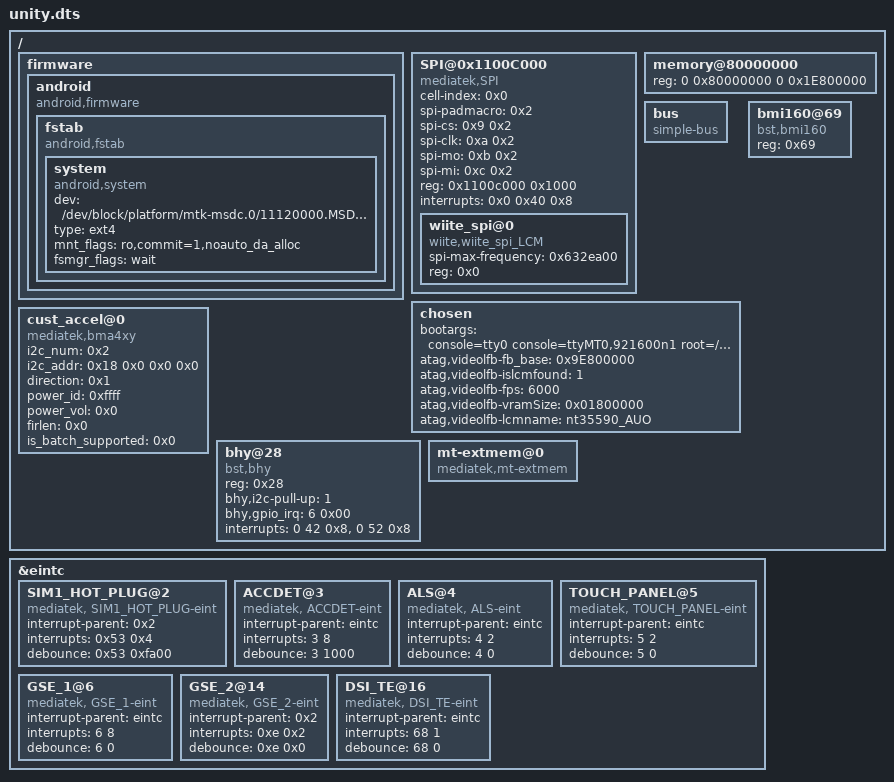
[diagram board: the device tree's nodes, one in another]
/dts-v1/;

/include/ "mt6580.dtsi"

&eintc {
	SIM1_HOT_PLUG@2 {
		compatible = "mediatek, SIM1_HOT_PLUG-eint";
		interrupt-parent = <0x2>;
		interrupts = <0x53 0x4>;
		debounce = <0x53 0xfa00>;
	};

	ACCDET@3 {
		compatible = "mediatek, ACCDET-eint";
		interrupt-parent = <&eintc>;
		interrupts = <3 8>;
		debounce = <3 1000>;
	};

	ALS@4 {
		compatible = "mediatek, ALS-eint";
		interrupt-parent = <&eintc>;
		interrupts = <4 2>;
		debounce = <4 0>;
	};

	TOUCH_PANEL@5 {
		compatible = "mediatek, TOUCH_PANEL-eint";
		interrupt-parent = <&eintc>;
		interrupts = <5 2>;
		debounce = <5 0>;
	};

	GSE_1@6 {
		compatible = "mediatek, GSE_1-eint";
		interrupt-parent = <&eintc>;
		interrupts = <6 8>;
		debounce = <6 0>;
	};

	GSE_2@14 {
		compatible = "mediatek, GSE_2-eint";
		interrupt-parent = <0x2>;
		interrupts = <0xe 0x2>;
		debounce = <0xe 0x0>;
	};

	DSI_TE@16 {
		compatible = "mediatek, DSI_TE-eint";
		interrupt-parent = <&eintc>;
		interrupts = <68 1>;
		debounce = <68 0>;
	};

};

/ {

	firmware {
		android {
			compatible = "android,firmware";
			fstab {
				compatible = "android,fstab";
				system {
					compatible = "android,system";
					dev = "/dev/block/platform/mtk-msdc.0/11120000.MSDC0/by-name/system";
					type = "ext4";
					mnt_flags = "ro,commit=1,noauto_da_alloc";
					fsmgr_flags = "wait";
				};
			};
		};
	};

	SPI@0x1100C000 {
		compatible = "mediatek,SPI";
		cell-index = <0x0>;
		spi-padmacro = <0x2>;
		spi-cs = <0x9 0x2>;
		spi-clk = <0xa 0x2>;
		spi-mo = <0xb 0x2>;
		spi-mi = <0xc 0x2>;
		reg = <0x1100c000 0x1000>;
		interrupts = <0x0 0x40 0x8>;

		wiite_spi@0 {
			compatible = "wiite,wiite_spi_LCM";
			spi-max-frequency = <0x632ea00>;
			reg = <0x0>;
		};
	};

	memory@80000000 {
		device_type = "memory";
		reg = <0 0x80000000 0 0x1E800000>;
	};

	bus {
		compatible = "simple-bus";
		#address-cells = <1>;
		#size-cells = <1>;
		ranges = <0 0 0 0xffffffff>;
	};

    /* chosen */
    chosen {
        bootargs = "console=tty0 console=ttyMT0,921600n1 root=/dev/ram initrd=0x84000000,0x400000 loglevel=8";
		/* fpga may has no lk, we need to specify display info here */
		/* fb buffer is reserved using this dts by memory node above */
		atag,videolfb-fb_base = <0x9E800000>;
		atag,videolfb-islcmfound = <1>;
		atag,videolfb-fps= <6000>;
		atag,videolfb-vramSize= <0x01800000>;
		atag,videolfb-lcmname= "nt35590_AUO";
    };
  /*  start sensor */
		cust_accel@0 {
			compatible = "mediatek,bma4xy";
			i2c_num = <0x2>;
			i2c_addr = <0x18 0x0 0x0 0x0>;
			direction = <0x1>;
			power_id = <0xffff>;
			power_vol = <0x0>;
			firlen = <0x0>;
			is_batch_supported = <0x0>;
		};

		bhy@28 {
			compatible = "bst,bhy";
			reg = <0x28>;
			bhy,i2c-pull-up = <1>;
			bhy,gpio_irq = <6 0x00>;
			interrupts = <0 42 0x8>,
				   <0 52 0x8>;
		};

		bmi160@69 {
			compatible = "bst,bmi160";
			reg = <0x69>;
		};

  /* end sensor */

	mt-extmem@0 {
		compatible = "mediatek,mt-extmem";
	};	
};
